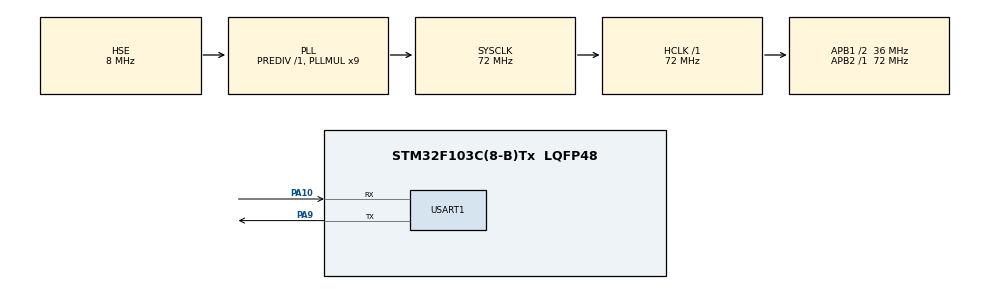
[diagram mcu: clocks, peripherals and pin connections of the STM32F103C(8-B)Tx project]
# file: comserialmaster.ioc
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Mcu.Family=STM32F1
Mcu.Name=STM32F103C(8-B)Tx
Mcu.Package=LQFP48
NVIC.PriorityGroup=NVIC_PRIORITYGROUP_4
PA10.Mode=Asynchronous
PA10.Signal=USART1_RX
PA13.Mode=Serial_Wire
PA13.Signal=SYS_JTMS-SWDIO
PA14.Mode=Serial_Wire
PA14.Signal=SYS_JTCK-SWCLK
PA9.Mode=Asynchronous
PA9.Signal=USART1_TX
PD0-OSC_IN.Mode=HSE-External-Oscillator
PD0-OSC_IN.Signal=RCC_OSC_IN
PD1-OSC_OUT.Mode=HSE-External-Oscillator
PD1-OSC_OUT.Signal=RCC_OSC_OUT
ProjectManager.HeapSize=0x200
ProjectManager.StackSize=0x400
ProjectManager.TargetToolchain=STM32CubeIDE
RCC.AHBFreq_Value=72000000
RCC.APB1CLKDivider=RCC_HCLK_DIV2
RCC.APB1Freq_Value=36000000
RCC.APB1TimFreq_Value=72000000
RCC.APB2Freq_Value=72000000
RCC.APB2TimFreq_Value=72000000
RCC.HCLKFreq_Value=72000000
RCC.PLLMUL=RCC_PLL_MUL9
RCC.PLLSourceVirtual=RCC_PLLSOURCE_HSE
RCC.SYSCLKFreq_VALUE=72000000
RCC.SYSCLKSource=RCC_SYSCLKSOURCE_PLLCLK
RCC.USBFreq_Value=72000000
USART1.VirtualMode=VM_ASYNC
board=custom

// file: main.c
/* USER CODE BEGIN Header */
/**
  ******************************************************************************
  * @file           : main.c
  * @brief          : UART Transmitter (untuk Receiver Debug)
  * @board          : STM32F103C8T6 (Blue Pill)
  ******************************************************************************
  */
#include "main.h"
#include <string.h>

UART_HandleTypeDef huart1;

/* USER CODE BEGIN PV */
uint8_t txFrame[7];
uint8_t data[5];
uint8_t SOF = 0xA5;
uint8_t chkSum;
/* USER CODE END PV */

void SystemClock_Config(void);
static void MX_GPIO_Init(void);
static void MX_USART1_UART_Init(void);

int main(void)
{
  HAL_Init();
  SystemClock_Config();
  MX_GPIO_Init();
  MX_USART1_UART_Init();

  while (1)
  {
    // Contoh data dikirim (bisa kamu ubah sesuai kebutuhan)
    data[0] = 10;
    data[1] = 20;
    data[2] = 30;
    data[3] = 40;
    data[4] = 50;

    // Hitung checksum
    chkSum = 0;
    for (int i = 0; i < 5; i++) chkSum += data[i];
    chkSum &= 0xFF;

    // Buat frame lengkap
    txFrame[0] = SOF;
    memcpy(&txFrame[1], data, 5);
    txFrame[6] = chkSum;

    // Kirim frame via UART1
    HAL_UART_Transmit(&huart1, txFrame, 7, HAL_MAX_DELAY);

    // Delay sebelum kirim lagi
    HAL_Delay(1000);
  }
}

/* USART1 init function */
static void MX_USART1_UART_Init(void)
{
  huart1.Instance = USART1;
  huart1.Init.BaudRate = 115200;
  huart1.Init.WordLength = UART_WORDLENGTH_8B;
  huart1.Init.StopBits = UART_STOPBITS_1;
  huart1.Init.Parity = UART_PARITY_NONE;
  huart1.Init.Mode = UART_MODE_TX_RX;
  huart1.Init.HwFlowCtl = UART_HWCONTROL_NONE;
  huart1.Init.OverSampling = UART_OVERSAMPLING_16;
  HAL_UART_Init(&huart1);
}

/* System Clock Configuration for STM32F103C8T6 @72MHz */
void SystemClock_Config(void)
{
  RCC_OscInitTypeDef RCC_OscInitStruct = {0};
  RCC_ClkInitTypeDef RCC_ClkInitStruct = {0};

  RCC_OscInitStruct.OscillatorType = RCC_OSCILLATORTYPE_HSE;
  RCC_OscInitStruct.HSEState = RCC_HSE_ON;
  RCC_OscInitStruct.HSEPredivValue = RCC_HSE_PREDIV_DIV1;
  RCC_OscInitStruct.PLL.PLLState = RCC_PLL_ON;
  RCC_OscInitStruct.PLL.PLLSource = RCC_PLLSOURCE_HSE;
  RCC_OscInitStruct.PLL.PLLMUL = RCC_PLL_MUL9;
  HAL_RCC_OscConfig(&RCC_OscInitStruct);

  RCC_ClkInitStruct.ClockType = RCC_CLOCKTYPE_HCLK | RCC_CLOCKTYPE_SYSCLK |
                                RCC_CLOCKTYPE_PCLK1 | RCC_CLOCKTYPE_PCLK2;
  RCC_ClkInitStruct.SYSCLKSource = RCC_SYSCLKSOURCE_PLLCLK;
  RCC_ClkInitStruct.AHBCLKDivider = RCC_SYSCLK_DIV1;
  RCC_ClkInitStruct.APB1CLKDivider = RCC_HCLK_DIV2;
  RCC_ClkInitStruct.APB2CLKDivider = RCC_HCLK_DIV1;
  HAL_RCC_ClockConfig(&RCC_ClkInitStruct, FLASH_LATENCY_2);
}

/* GPIO init */
static void MX_GPIO_Init(void)
{
  __HAL_RCC_GPIOA_CLK_ENABLE();
}
